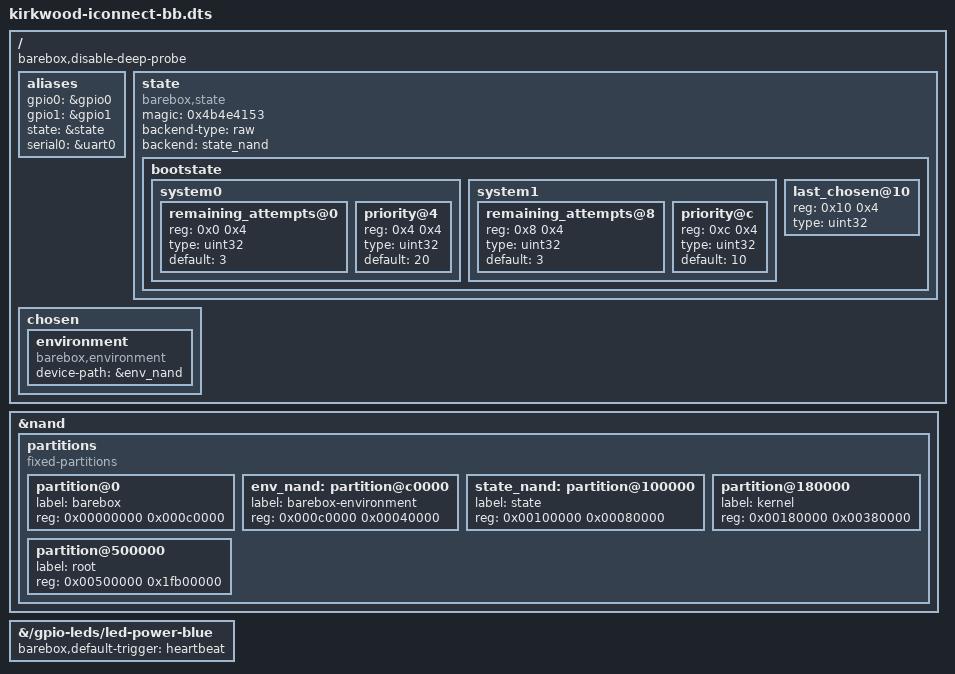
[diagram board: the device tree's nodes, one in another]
// SPDX-License-Identifier: GPL-2.0-or-later
/*
 * barebox specific additions for the Iomega iConnect
 *
 * NAND layout (512 MiB, 128 KiB erase blocks, 2 KiB pages):
 *
 *   0x00000000 - 0x000bffff  barebox              (768 KiB, kwbimage v0)
 *   0x000c0000 - 0x000fffff  barebox-environment  (256 KiB, 1 spare block)
 *   0x00100000 - 0x0017ffff  state                (512 KiB, barebox state)
 *   0x00180000 - 0x004fffff  kernel               (3.5 MiB, raw zImage)
 *   0x00500000 - 0x1fffffff  root                 (UBI)
 *
 * The upstream Linux partition table is replaced because its "uboot"
 * (0x0-0xc0000) and "env" (0xa0000-0xc0000) partitions overlap, which
 * barebox refuses to register.
 */

#include "arm/marvell/kirkwood-iconnect.dts"

/ {
	barebox,disable-deep-probe;

	/*
	 * Fixed GPIO numbering as in Linux and the Marvell documentation:
	 * bank 0 is GPIO 0-31, bank 1 is GPIO 32-49.
	 */
	aliases {
		gpio0 = &gpio0;
		gpio1 = &gpio1;
		/* the state driver names the state after its alias */
		state = &state;
		/* barebox adds console=ttyS0,115200n8 only for aliased UARTs */
		serial0 = &uart0;
	};

	state: state {
		magic = <0x4b4e4153>;	/* "KNAS" */
		compatible = "barebox,state";
		backend-type = "raw";
		backend = <&state_nand>;
		/* NAND needs erase before write: circular storage type */
		#address-cells = <1>;
		#size-cells = <1>;

		bootstate {
			#address-cells = <1>;
			#size-cells = <1>;

			/* names must match RAUC's bootname= and barebox bootchooser targets */
			system0 {
				#address-cells = <1>;
				#size-cells = <1>;

				remaining_attempts@0 {
					reg = <0x0 0x4>;
					type = "uint32";
					default = <3>;
				};
				priority@4 {
					reg = <0x4 0x4>;
					type = "uint32";
					default = <20>;
				};
			};

			system1 {
				#address-cells = <1>;
				#size-cells = <1>;

				remaining_attempts@8 {
					reg = <0x8 0x4>;
					type = "uint32";
					default = <3>;
				};
				priority@c {
					reg = <0xc 0x4>;
					type = "uint32";
					default = <10>;
				};
			};

			last_chosen@10 {
				reg = <0x10 0x4>;
				type = "uint32";
			};
		};
	};

	chosen {
		/*
		 * Upstream hardcodes the location where the Iomega stock
		 * loader used to put its initrd. barebox only rewrites these
		 * properties when an initrd is actually passed, so without
		 * removing them every kernel booted without initrd tries to
		 * unpack garbage from 0x4500040.
		 */
		/delete-property/ linux,initrd-start;
		/delete-property/ linux,initrd-end;

		environment {
			compatible = "barebox,environment";
			device-path = &env_nand;
		};
	};
};

&nand {
	/delete-node/ partition@0;
	/delete-node/ partition@a0000;
	/delete-node/ partition@100000;
	/delete-node/ partition@540000;
	/delete-node/ partition@980000;

	partitions {
		compatible = "fixed-partitions";
		#address-cells = <1>;
		#size-cells = <1>;

		partition@0 {
			label = "barebox";
			reg = <0x00000000 0x000c0000>;
		};

		env_nand: partition@c0000 {
			label = "barebox-environment";
			reg = <0x000c0000 0x00040000>;
		};

		state_nand: partition@100000 {
			label = "state";
			reg = <0x00100000 0x00080000>;
		};

		partition@180000 {
			label = "kernel";
			reg = <0x00180000 0x00380000>;
		};

		partition@500000 {
			label = "root";
			reg = <0x00500000 0x1fb00000>;
		};
	};
};

&{/gpio-leds/led-power-blue} {
	barebox,default-trigger = "heartbeat";
};
